# COMPUTE_CLUSTER0_CFG_WRAP_0_MSMC_PBIST0 register map
Vendor: Texas Instruments
Peripheral module from a debugger description file (folder J721S2).
Registers are 32-bit, read-write, reset 0x0 unless marked. A register's access mark holds for its fields unless they carry their own. Offsets are as the file gives them; lines under a group give offsets from that group; [hi:lo] are bit positions; {n}, {i} and the like mark numbered series; 'fields as' and 'values as' point back to an identical list; <NAME> marks a mode.

## COMPUTE_CLUSTER0_CFG_WRAP_0_MSMC_PBIST0
{0x100+4i} __VBUSP4_CFG_MSMC_PBIST0__CFG_MSMC_PBIST0_A{i} (i=0..3) — Variable Address Registers
  [15:0] A{i} — Variable Address Register {i} [A{i}]
{0x110+4i} __VBUSP4_CFG_MSMC_PBIST0__CFG_MSMC_PBIST0_L{i} (i=0..3) — Variable Loop Count Registers
  [15:0] L{i} — Variable Loop Count Register {i} [L{i}]
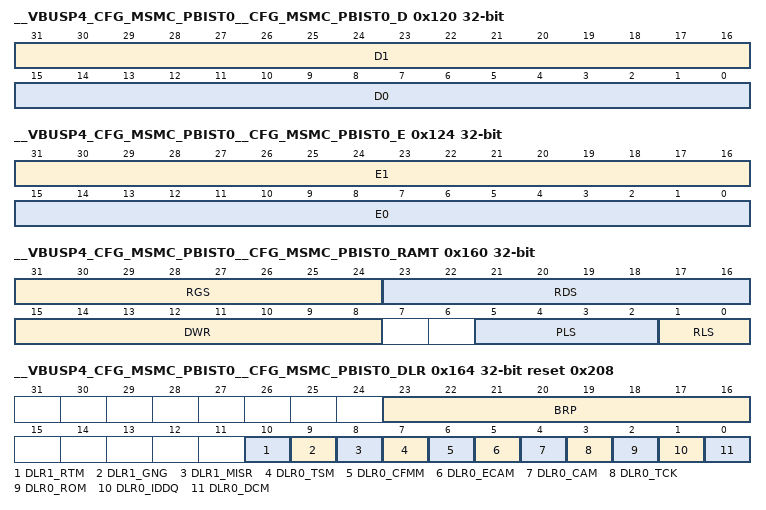
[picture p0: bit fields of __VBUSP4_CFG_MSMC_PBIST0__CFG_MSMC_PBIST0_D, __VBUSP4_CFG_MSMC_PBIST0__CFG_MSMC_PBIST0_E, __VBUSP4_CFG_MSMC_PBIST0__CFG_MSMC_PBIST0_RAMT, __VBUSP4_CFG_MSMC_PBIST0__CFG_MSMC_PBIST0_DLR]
0x120 __VBUSP4_CFG_MSMC_PBIST0__CFG_MSMC_PBIST0_D — Data Registers
  [31:16] D1 — DD1 Data Register Upper 16 [D1]
  [15:0] D0 — DD0 Data Register Lower 16 [D0]
0x124 __VBUSP4_CFG_MSMC_PBIST0__CFG_MSMC_PBIST0_E — Data Registers
  [31:16] E1 — EE1 Data Register Upper 16 [E1]
  [15:0] E0 — EE0 Data Register Lower 16 [E0]
{0x130+4i} __VBUSP4_CFG_MSMC_PBIST0__CFG_MSMC_PBIST0_CA{i} (i=0..3) — Constant Address Registers
  [15:0] CA{i} — Constant Address Register {i} [CA{i}]
{0x140+4i} __VBUSP4_CFG_MSMC_PBIST0__CFG_MSMC_PBIST0_CL{i} (i=0..3) — Constant Loop Count Registers
  [15:0] CL{i} — Constant Loop Count Register {i} [CL{i}]
{0x150+4i} __VBUSP4_CFG_MSMC_PBIST0__CFG_MSMC_PBIST0_I{i} (i=0..3) — Constant Increment Registers
  [15:0] I0 — Constant Increment Register {i} [I{i}]
0x160 __VBUSP4_CFG_MSMC_PBIST0__CFG_MSMC_PBIST0_RAMT — RAM Configuration Register
  [31:24] RGS — RAM Group Select RGS
  [23:16] RDS — Return Data select RDS
  [15:8] DWR — Data Width Register DWR
  [5:2] PLS — Pipeline Latency Select
  [1:0] RLS — RAM Latency Select
0x164 __VBUSP4_CFG_MSMC_PBIST0__CFG_MSMC_PBIST0_DLR reset 0x208 — Datalogger Register
  [23:16] BRP — Datalogger 2 [BRP]
  [10] DLR1_RTM — Retention testing mode
  [9] DLR1_GNG — GO / NO-GO testing mode
  [8] DLR1_MISR — MISR testing mode [mainly for ROM testing]
  [7] DLR0_TSM — Time stamp mode
  [6] DLR0_CFMM — Column Fail Masking mode
  [5] DLR0_ECAM — Emulation cache access mode
  [4] DLR0_CAM — Config access mode
  [3] DLR0_TCK — TCK Gated mode
  [2] DLR0_ROM — ROM-based testing mode
  [1] DLR0_IDDQ — IDDQ testing mode
  [0] DLR0_DCM — Distributed Compare mode
0x168 __VBUSP4_CFG_MSMC_PBIST0__CFG_MSMC_PBIST0_CMS — Clock-Mux Select Register
  [3:0] CMS — Clock Mux Select [CMS]
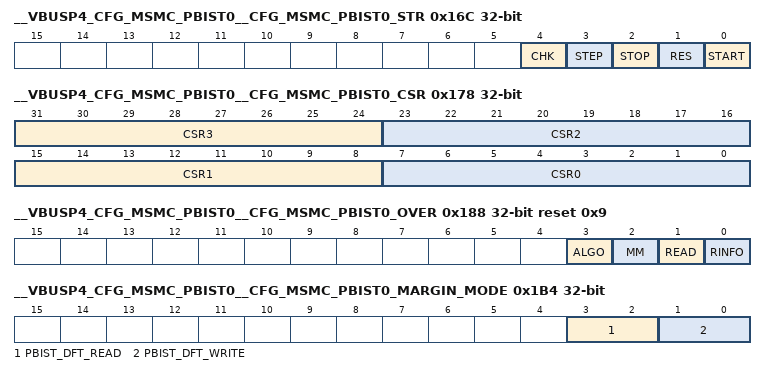
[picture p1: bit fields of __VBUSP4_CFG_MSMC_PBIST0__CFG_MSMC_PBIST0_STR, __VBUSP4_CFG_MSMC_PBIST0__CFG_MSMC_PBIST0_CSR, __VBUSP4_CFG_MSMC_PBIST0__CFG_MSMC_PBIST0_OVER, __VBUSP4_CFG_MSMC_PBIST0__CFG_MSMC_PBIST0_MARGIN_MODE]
0x16C __VBUSP4_CFG_MSMC_PBIST0__CFG_MSMC_PBIST0_STR — Program Control Register
  [4] CHK — Check MISR mode
  [3] STEP — Step / Step for emulation mode
  [2] STOP
  [1] RES — Resume / Emulation read
  [0] START — Start / Time Stamp mode restart
0x170 __VBUSP4_CFG_MSMC_PBIST0__CFG_MSMC_PBIST0_SCR reset 0x76543210FEDCBA98 — Address Scrambling Register
  [8n+7:8n] SCR{n} (n=0..7) — Address Scrambling Register {n}
0x178 __VBUSP4_CFG_MSMC_PBIST0__CFG_MSMC_PBIST0_CSR — Chip Select Register
  [31:24] CSR3 — Chip Select 3 [CSR3]
  [23:16] CSR2 — Chip Select 2 [CSR2]
  [15:8] CSR1 — Chip Select 1[CSR1]
  [7:0] CSR0 — Chip Select 0 [CSR0]
0x17C __VBUSP4_CFG_MSMC_PBIST0__CFG_MSMC_PBIST0_FDLY reset 0x68 — Fail Delay Register
  [7:0] FDLY — Fail Delay [FDLY]
0x180 __VBUSP4_CFG_MSMC_PBIST0__CFG_MSMC_PBIST0_PACT — PACT Register
  [0] PACT — PBIST Activate [PACT]
0x184 __VBUSP4_CFG_MSMC_PBIST0__CFG_MSMC_PBIST0_PID — PBIST_ID Register
  [4:0] PID — PBIST ID
0x188 __VBUSP4_CFG_MSMC_PBIST0__CFG_MSMC_PBIST0_OVER reset 0x9 — Override Register
  [3] ALGO — PBIST Override Algorithm Override
  [2] MM — PBIST Override Multiple Memory
  [1] READ — PBIST Override READ Override
  [0] RINFO — PBIST Override RINFO Override
0x190 __VBUSP4_CFG_MSMC_PBIST0__CFG_MSMC_PBIST0_FSRF ro — Fail Status Fail Register
  [32] FRSF1 — Fail Status Fail - Port 1 [FSRF1]
  [0] FRSF0 — Fail Status Fail - Port 0 [FSRF0]
0x198 __VBUSP4_CFG_MSMC_PBIST0__CFG_MSMC_PBIST0_FSRC ro — Fail Status Count Register
  [35:32] FSRC1 — Fail Status Count - Port 1 [FSRC1]
  [3:0] FSRC0 — Fail Status Count - Port 0 [FSRC0]
0x1A0 __VBUSP4_CFG_MSMC_PBIST0__CFG_MSMC_PBIST0_FSRA ro — Fail Status Address Register
  [47:32] FSRA1 — Fail Status Address - Port 1 [FSRA1]
  [15:0] FSRA0 — Fail Status Address - Port 0 [FSRA0]
0x1A8 __VBUSP4_CFG_MSMC_PBIST0__CFG_MSMC_PBIST0_FSRDL0 ro — Fail Status Data Registers
  [31:0] FSRDL0 — Fail Status Data - Port 0 [FSRDL0]
0x1B0 __VBUSP4_CFG_MSMC_PBIST0__CFG_MSMC_PBIST0_FSRDL1 ro — Fail Status Data Registers
  [31:0] FSRDL1 — Fail Status Data - Port 1 [FSRDL1]
0x1B4 __VBUSP4_CFG_MSMC_PBIST0__CFG_MSMC_PBIST0_MARGIN_MODE ro — Fail Status Fail Register
  [3:2] PBIST_DFT_READ — pbist_dft_read[1:0]
  [1:0] PBIST_DFT_WRITE — pbist_dft_write[1:0]
0x1B8 __VBUSP4_CFG_MSMC_PBIST0__CFG_MSMC_PBIST0_WRENZ ro — Fail Status Fail Register
  [1:0] WRENZ — pbist_ram_wrenz[1:0]
0x1BC __VBUSP4_CFG_MSMC_PBIST0__CFG_MSMC_PBIST0_PAGE_PGS ro — Fail Status Fail Register
  [1:0] PGS — pbist_ram_pgs[1:0]
0x1C0 __VBUSP4_CFG_MSMC_PBIST0__CFG_MSMC_PBIST0_ROM reset 0x3 — ROM Mask Register
  [1:0] ROM — ROM Mask [ROM]
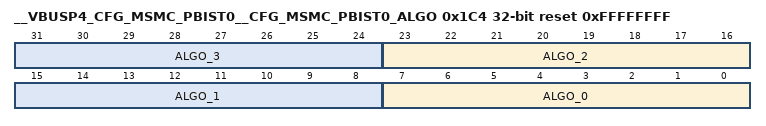
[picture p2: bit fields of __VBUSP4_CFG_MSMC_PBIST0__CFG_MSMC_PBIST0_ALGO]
0x1C4 __VBUSP4_CFG_MSMC_PBIST0__CFG_MSMC_PBIST0_ALGO reset 0xFFFFFFFF — Algorithm Mask Register
  [8n+7:8n] ALGO_{n} (n=0..3) — ROM Algorithm Mask {n} [ALGO {n}]
0x1C8 __VBUSP4_CFG_MSMC_PBIST0__CFG_MSMC_PBIST0_RINFO reset 0xFFFFFFFFFFFFFFFF — RAM Info Mask Register
  [8n+39:8n+32] U{n} (n=0..3) — RAM Info Mask Upper {n} [RINFOU{n}]
  [8n+7:8n] L{n} (n=0..3) — RAM Info Mask Lower {n} [RINFOL{n}]
